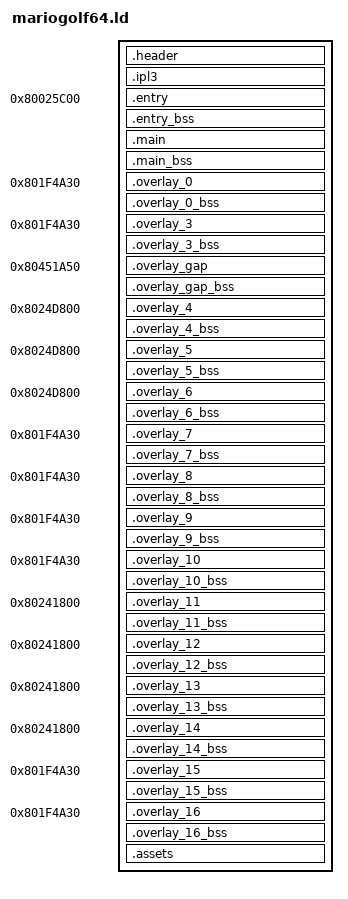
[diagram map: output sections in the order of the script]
SECTIONS
{
    __romPos = 0;
    header_ROM_START = __romPos;
    header_VRAM = ADDR(.header);
    .header : AT(header_ROM_START)
    {
        FILL(0x00000000);
        header_DATA_START = .;
        build/asm/header.o(.data);
        header_DATA_END = .;
        header_DATA_SIZE = ABSOLUTE(header_DATA_END - header_DATA_START);
    }
    __romPos += SIZEOF(.header);
    header_ROM_END = __romPos;
    header_VRAM_END = .;

    ipl3_ROM_START = __romPos;
    ipl3_VRAM = ADDR(.ipl3);
    .ipl3 : AT(ipl3_ROM_START)
    {
        FILL(0x00000000);
        ipl3_DATA_START = .;
        build/assets/ipl3.o(.data);
        ipl3_DATA_END = .;
        ipl3_DATA_SIZE = ABSOLUTE(ipl3_DATA_END - ipl3_DATA_START);
    }
    __romPos += SIZEOF(.ipl3);
    ipl3_ROM_END = __romPos;
    ipl3_VRAM_END = .;

    entry_ROM_START = __romPos;
    entry_VRAM = ADDR(.entry);
    .entry 0x80025C00 : AT(entry_ROM_START)
    {
        FILL(0x00000000);
        entry_TEXT_START = .;
        build/src/entry/entry.o(.text);
        entry_TEXT_END = .;
        entry_TEXT_SIZE = ABSOLUTE(entry_TEXT_END - entry_TEXT_START);
        entry_DATA_START = .;
        build/src/entry/entry.o(.data);
        entry_DATA_END = .;
        entry_DATA_SIZE = ABSOLUTE(entry_DATA_END - entry_DATA_START);
        entry_RODATA_START = .;
        build/src/entry/entry.o(.rodata);
        entry_RODATA_END = .;
        entry_RODATA_SIZE = ABSOLUTE(entry_RODATA_END - entry_RODATA_START);
    }
    entry_bss_VRAM = ADDR(.entry_bss);
    .entry_bss (NOLOAD) :
    {
        FILL(0x00000000);
        entry_BSS_START = .;
        build/src/entry/entry.o(.bss);
        entry_BSS_END = .;
        entry_BSS_SIZE = ABSOLUTE(entry_BSS_END - entry_BSS_START);
    }
    __romPos += SIZEOF(.entry);
    __romPos = ALIGN(__romPos, 16);
    entry_ROM_END = __romPos;
    entry_VRAM_END = .;

    main_ROM_START = __romPos;
    main_VRAM = ADDR(.main);
    .main entry_VRAM_END : AT(main_ROM_START)
    {
        FILL(0x00000000);
        main_TEXT_START = .;
        build/src/libnusys/mainlib/nupireadrom.o(.text);
        build/asm/1130.o(.text);
        build/asm/17B0.o(.text);
        build/src/libnusys/mainlib/nugfxinit.o(.text);
        build/asm/37B0.o(.text);
        build/asm/4650.o(.text);
        build/asm/4840.o(.text);
        build/asm/4CE0.o(.text);
        build/asm/5A40.o(.text);
        build/asm/DCE0.o(.text);
        build/asm/E260.o(.text);
        build/asm/142B0.o(.text);
        build/asm/193D0.o(.text);
        build/asm/1B4A0.o(.text);
        build/asm/1EEF0.o(.text);
        build/asm/207E0.o(.text);
        build/asm/28590.o(.text);
        build/asm/299A0.o(.text);
        build/asm/2B4E0.o(.text);
        build/asm/2B800.o(.text);
        build/asm/2BFF0.o(.text);
        build/asm/2D290.o(.text);
        build/asm/2D5C0.o(.text);
        build/asm/2E3E0.o(.text);
        build/asm/2FD00.o(.text);
        build/asm/34FA0.o(.text);
        build/asm/396C0.o(.text);
        build/asm/40180.o(.text);
        build/asm/414A0.o(.text);
        build/src/mgu/mtxutil.o(.text);
        build/asm/43140.o(.text);
        build/asm/43810.o(.text);
        build/asm/45400.o(.text);
        build/asm/456C0.o(.text);
        build/asm/49E90.o(.text);
        build/asm/4A5A0.o(.text);
        build/asm/4C3D0.o(.text);
        build/asm/4C770.o(.text);
        build/asm/51900.o(.text);
        build/asm/526B0.o(.text);
        build/asm/52FF0.o(.text);
        build/asm/53D10.o(.text);
        build/asm/5B620.o(.text);
        build/asm/68500.o(.text);
        build/asm/70E10.o(.text);
        build/src/main/func_80099490.o(.text);
        build/asm/748B0.o(.text);
        build/asm/78330.o(.text);
        build/asm/78D10.o(.text);
        build/asm/79370.o(.text);
        build/asm/79640.o(.text);
        build/asm/798B0.o(.text);
        build/asm/7A840.o(.text);
        build/asm/7AF60.o(.text);
        build/asm/7B140.o(.text);
        build/asm/7BB30.o(.text);
        build/asm/7BBB0.o(.text);
        build/asm/7BC00.o(.text);
        build/asm/7BDE0.o(.text);
        build/asm/7BE90.o(.text);
        build/asm/7BF20.o(.text);
        build/asm/7BFB0.o(.text);
        build/asm/7C060.o(.text);
        build/asm/7C0F0.o(.text);
        build/asm/7C170.o(.text);
        build/asm/7C6D0.o(.text);
        build/asm/7C720.o(.text);
        build/src/libnusys/mainlib/nuprenmifuncset.o(.text);
        build/asm/7C830.o(.text);
        build/src/libnusys/mainlib/nugfxfuncset.o(.text);
        build/src/libnusys/mainlib/nugfxswapcfbfuncset.o(.text);
        build/src/libnusys/mainlib/nugfxswapcfb.o(.text);
        build/src/libnusys/mainlib/nugfxtaskallendwait.o(.text);
        build/src/libnusys/mainlib/nugfxretracewait.o(.text);
        build/src/libnusys/mainlib/nugfxdisplayoff.o(.text);
        build/src/libnusys/mainlib/nugfxdisplayon.o(.text);
        build/src/libnusys/mainlib/nupiinit.o(.text);
        build/src/libnusys/mainlib/nupiinitsram.o(.text);
        build/src/libnusys/mainlib/nupireadwritesram.o(.text);
        build/src/libnusys/mainlib/nucontinit.o(.text);
        build/src/libnusys/mainlib/nucontdatagetex.o(.text);
        build/asm/7CD60.o(.text);
        build/src/libnusys/mainlib/nucontrmbstart.o(.text);
        build/src/libnusys/mainlib/nucontrmbcheck.o(.text);
        build/asm/7D3B0.o(.text);
        build/asm/7D4A0.o(.text);
        build/src/libnusys/mainlib/nucontgbpakopen.o(.text);
        build/src/libnusys/mainlib/nucontgbpakgetstatus.o(.text);
        build/src/libnusys/mainlib/nucontgbpakpower.o(.text);
        build/src/libnusys/mainlib/nucontgbpakreadid.o(.text);
        build/src/libnusys/mainlib/nucontgbpakreadwrite.o(.text);
        build/src/libnusys/mainlib/nucontgbpakcheck.o(.text);
        build/asm/7D7A0.o(.text);
        build/asm/7D970.o(.text);
        build/asm/7DE70.o(.text);
        build/asm/7DF90.o(.text);
        build/src/libnusys/mainlib/nucontdatalock.o(.text);
        build/src/libnusys/mainlib/nucontqueryread.o(.text);
        build/src/libultra/os/getcurrfaultthread.o(.text);
        build/src/libultra/os/setintmask.o(.text);
        build/src/libultra/io/pimgr.o(.text);
        build/src/libultra/io/epirawdma.o(.text);
        build/src/libultra/io/epidma.o(.text);
        build/src/libultra/io/epilinkhandle.o(.text);
        build/src/libultra/io/cartrominit.o(.text);
        build/src/libultra/io/devmgr.o(.text);
        build/src/libultra/io/piacs.o(.text);
        build/src/libultra/io/aigetlen.o(.text);
        build/src/libultra/io/aigetstat.o(.text);
        build/src/libultra/io/aisetfreq.o(.text);
        build/src/libultra/io/aisetnextbuf.o(.text);
        build/src/libultra/audio/drvrnew.o(.text);
        build/src/libultra/audio/load.o(.text);
        build/src/libultra/audio/auxbus.o(.text);
        build/src/libultra/audio/env.o(.text);
        build/src/libultra/audio/filter.o(.text);
        build/src/libultra/audio/mainbus.o(.text);
        build/src/libultra/audio/resample.o(.text);
        build/src/libultra/audio/reverb.o(.text);
        build/src/libultra/audio/save.o(.text);
        build/src/libultra/audio/sl.o(.text);
        build/src/libultra/audio/heapinit.o(.text);
        build/src/libultra/audio/heapalloc.o(.text);
        build/src/libultra/audio/copy.o(.text);
        build/src/libultra/os/invaldcache.o(.text);
        build/src/libultra/os/invalicache.o(.text);
        build/src/libultra/os/writebackdcache.o(.text);
        build/src/libultra/os/writebackdcacheall.o(.text);
        build/src/libultra/io/contquery.o(.text);
        build/src/libultra/io/contreaddata.o(.text);
        build/src/libultra/io/controller.o(.text);
        build/src/libultra/os/virtualtophysical.o(.text);
        build/src/libultra/gu/align.o(.text);
        build/src/libultra/gu/cosf.o(.text);
        build/src/libultra/gu/lookat.o(.text);
        build/src/libultra/gu/lookathil.o(.text);
        build/src/libultra/gu/lookatref.o(.text);
        build/src/libultra/gu/mtxcatf.o(.text);
        build/src/libultra/gu/mtxcatl.o(.text);
        build/src/libultra/gu/ortho.o(.text);
        build/src/libultra/gu/perspective.o(.text);
        build/src/libultra/gu/position.o(.text);
        build/src/libultra/gu/random.o(.text);
        build/src/libultra/gu/rotate.o(.text);
        build/src/libultra/gu/rotaterpy.o(.text);
        build/src/libultra/gu/scale.o(.text);
        build/src/libultra/gu/sinf.o(.text);
        build/src/libultra/gu/translate.o(.text);
        build/src/libultra/libc/bcopy.o(.text);
        build/src/libultra/libc/bzero.o(.text);
        build/src/libultra/libc/string.o(.text);
        build/src/libultra/libc/sprintf.o(.text);
        build/src/libultra/libc/syncprintf.o(.text);
        build/src/libultra/os/createmesgqueue.o(.text);
        build/src/libultra/os/jammesg.o(.text);
        build/src/libultra/os/recvmesg.o(.text);
        build/src/libultra/os/sendmesg.o(.text);
        build/src/libultra/os/seteventmesg.o(.text);
        build/src/libultra/io/dpsetstat.o(.text);
        build/src/libultra/io/dpctr.o(.text);
        build/src/libultra/os/getcount.o(.text);
        build/src/libultra/io/sptask.o(.text);
        build/src/libultra/io/sptaskyield.o(.text);
        build/src/libultra/io/sptaskyielded.o(.text);
        build/src/libultra/sched/sched.o(.text);
        build/src/libultra/io/sirawdma.o(.text);
        build/src/libultra/io/siacs.o(.text);
        build/src/libultra/os/createthread.o(.text);
        build/src/libultra/os/destroythread.o(.text);
        build/src/libultra/os/getthreadpri.o(.text);
        build/src/libultra/os/setthreadpri.o(.text);
        build/src/libultra/os/startthread.o(.text);
        build/src/libultra/os/stopthread.o(.text);
        build/src/libultra/os/dequeuethread.o(.text);
        build/src/libultra/os/yieldthread.o(.text);
        build/src/libultra/os/gettime.o(.text);
        build/src/libultra/os/settimer.o(.text);
        build/src/libultra/os/timerintr.o(.text);
        build/src/libultra/os/maptlb.o(.text);
        build/src/libultra/os/probetlb.o(.text);
        build/src/libultra/os/unmaptlb.o(.text);
        build/src/libultra/os/unmaptlball.o(.text);
        build/src/libultra/io/vigetcurrframebuf.o(.text);
        build/src/libultra/io/vigetnextframebuf.o(.text);
        build/src/libultra/io/vigetmode.o(.text);
        build/src/libultra/io/vimgr.o(.text);
        build/src/libultra/io/visetevent.o(.text);
        build/src/libultra/io/visetmode.o(.text);
        build/src/libultra/io/visetspecial.o(.text);
        build/src/libultra/io/visetyscale.o(.text);
        build/src/libultra/io/viswapbuf.o(.text);
        build/src/libultra/io/viswapcontext.o(.text);
        build/src/libultra/io/viblack.o(.text);
        build/src/libultra/io/gbpakinit.o(.text);
        build/src/libultra/io/gbpakgetstatus.o(.text);
        build/src/libultra/io/gbpakpower.o(.text);
        build/src/libultra/io/gbpakreadwrite.o(.text);
        build/src/libultra/io/gbpakreadid.o(.text);
        build/src/libultra/io/gbpakcheckconnector.o(.text);
        build/src/libultra/io/motor.o(.text);
        build/src/libultra/io/pfsgetstatus.o(.text);
        build/src/libultra/io/pfsselectbank.o(.text);
        build/src/libultra/io/contpfs.o(.text);
        build/src/libultra/io/contramread.o(.text);
        build/src/libultra/io/contramwrite.o(.text);
        build/src/libultra/os/parameters.o(.text);
        build/src/libultra/os/afterprenmi.o(.text);
        build/src/libultra/os/initialize.o(.text);
        build/src/libultra/os/exceptasm.o(.text);
        build/src/libultra/os/interrupt.o(.text);
        build/src/libultra/os/setglobalintmask.o(.text);
        build/src/libultra/os/resetglobalintmask.o(.text);
        build/src/libultra/io/pirawdma.o(.text);
        build/src/libultra/io/pigetcmdq.o(.text);
        build/src/libultra/io/epirawread.o(.text);
        build/src/libultra/io/epirawwrite.o(.text);
        build/src/libultra/io/ai.o(.text);
        build/src/libultra/gu/sqrtf.o(.text);
        build/src/libultra/libc/bcmp.o(.text);
        build/src/libultra/libc/xprintf.o(.text);
        build/src/libultra/io/dpsetnextbuf.o(.text);
        build/src/libultra/os/getcause.o(.text);
        build/src/libultra/os/getsr.o(.text);
        build/src/libultra/os/setcompare.o(.text);
        build/src/libultra/os/setfpccsr.o(.text);
        build/src/libultra/os/setsr.o(.text);
        build/src/libultra/os/setwatchlo.o(.text);
        build/src/libultra/io/sp.o(.text);
        build/src/libultra/io/spgetstat.o(.text);
        build/src/libultra/io/spsetstat.o(.text);
        build/src/libultra/io/spsetpc.o(.text);
        build/src/libultra/io/sprawdma.o(.text);
        build/src/libultra/io/sirawread.o(.text);
        build/src/libultra/io/sirawwrite.o(.text);
        build/src/libultra/io/crc.o(.text);
        build/src/libultra/os/maptlbrdb.o(.text);
        build/src/libultra/io/viinit.o(.text);
        build/src/libultra/io/vigetcurrcontext.o(.text);
        build/src/libultra/io/gbpaksetbank.o(.text);
        build/src/libultra/io/pfsisplug.o(.text);
        build/src/libultra/libc/xlitob.o(.text);
        build/src/libultra/libc/xldtob.o(.text);
        build/src/libultra/io/dp.o(.text);
        build/src/libultra/io/si.o(.text);
        build/src/libultra/libc/ldiv.o(.text);
        build/src/libkmc/atan.o(.text);
        build/src/libkmc/memset.o(.text);
        build/src/libkmc/rand.o(.text);
        build/asm/8E660.o(.text);
        build/src/libkmc/strcmp.o(.text);
        build/src/libkmc/_matherr.o(.text);
        build/src/libkmc/mmuldi3.o(.text);
        build/src/libkmc/mcvtld.o(.text);
        build/src/libkmc/matherr.o(.text);
        build/asm/8F250.o(.text);
        main_TEXT_END = .;
        main_TEXT_SIZE = ABSOLUTE(main_TEXT_END - main_TEXT_START);
        main_DATA_START = .;
        build/src/libnusys/mainlib/nupireadrom.o(.data);
        build/asm/1130.o(.data);
        build/asm/17B0.o(.data);
        build/src/libnusys/mainlib/nugfxinit.o(.data);
        build/asm/37B0.o(.data);
        build/asm/4650.o(.data);
        build/asm/4840.o(.data);
        build/asm/4CE0.o(.data);
        build/asm/5A40.o(.data);
        build/asm/DCE0.o(.data);
        build/asm/E260.o(.data);
        build/asm/142B0.o(.data);
        build/asm/193D0.o(.data);
        build/asm/1B4A0.o(.data);
        build/asm/1EEF0.o(.data);
        build/asm/207E0.o(.data);
        build/asm/28590.o(.data);
        build/asm/299A0.o(.data);
        build/asm/2B4E0.o(.data);
        build/asm/2B800.o(.data);
        build/asm/2BFF0.o(.data);
        build/asm/2D290.o(.data);
        build/asm/2D5C0.o(.data);
        build/asm/2E3E0.o(.data);
        build/asm/2FD00.o(.data);
        build/asm/34FA0.o(.data);
        build/asm/396C0.o(.data);
        build/asm/40180.o(.data);
        build/asm/414A0.o(.data);
        build/src/mgu/mtxutil.o(.data);
        build/asm/43140.o(.data);
        build/asm/43810.o(.data);
        build/asm/45400.o(.data);
        build/asm/456C0.o(.data);
        build/asm/49E90.o(.data);
        build/asm/4A5A0.o(.data);
        build/asm/4C3D0.o(.data);
        build/asm/4C770.o(.data);
        build/asm/51900.o(.data);
        build/asm/526B0.o(.data);
        build/asm/52FF0.o(.data);
        build/asm/53D10.o(.data);
        build/asm/5B620.o(.data);
        build/asm/68500.o(.data);
        build/asm/70E10.o(.data);
        build/src/main/func_80099490.o(.data);
        build/asm/748B0.o(.data);
        build/asm/78330.o(.data);
        build/asm/78D10.o(.data);
        build/asm/79370.o(.data);
        build/asm/79640.o(.data);
        build/asm/798B0.o(.data);
        build/asm/7A840.o(.data);
        build/asm/7AF60.o(.data);
        build/asm/7B140.o(.data);
        build/asm/7BB30.o(.data);
        build/asm/7BBB0.o(.data);
        build/asm/7BC00.o(.data);
        build/asm/7BDE0.o(.data);
        build/asm/7BE90.o(.data);
        build/asm/7BF20.o(.data);
        build/asm/7BFB0.o(.data);
        build/asm/7C060.o(.data);
        build/asm/7C0F0.o(.data);
        build/asm/7C170.o(.data);
        build/asm/7C6D0.o(.data);
        build/asm/7C720.o(.data);
        build/src/libnusys/mainlib/nuprenmifuncset.o(.data);
        build/asm/7C830.o(.data);
        build/src/libnusys/mainlib/nugfxfuncset.o(.data);
        build/src/libnusys/mainlib/nugfxswapcfbfuncset.o(.data);
        build/src/libnusys/mainlib/nugfxswapcfb.o(.data);
        build/src/libnusys/mainlib/nugfxtaskallendwait.o(.data);
        build/src/libnusys/mainlib/nugfxretracewait.o(.data);
        build/src/libnusys/mainlib/nugfxdisplayoff.o(.data);
        build/src/libnusys/mainlib/nugfxdisplayon.o(.data);
        build/src/libnusys/mainlib/nupiinit.o(.data);
        build/src/libnusys/mainlib/nupiinitsram.o(.data);
        build/src/libnusys/mainlib/nupireadwritesram.o(.data);
        build/src/libnusys/mainlib/nucontinit.o(.data);
        build/src/libnusys/mainlib/nucontdatagetex.o(.data);
        build/asm/7CD60.o(.data);
        build/src/libnusys/mainlib/nucontrmbstart.o(.data);
        build/src/libnusys/mainlib/nucontrmbcheck.o(.data);
        build/asm/7D3B0.o(.data);
        build/asm/7D4A0.o(.data);
        build/src/libnusys/mainlib/nucontgbpakopen.o(.data);
        build/src/libnusys/mainlib/nucontgbpakgetstatus.o(.data);
        build/src/libnusys/mainlib/nucontgbpakpower.o(.data);
        build/src/libnusys/mainlib/nucontgbpakreadid.o(.data);
        build/src/libnusys/mainlib/nucontgbpakreadwrite.o(.data);
        build/src/libnusys/mainlib/nucontgbpakcheck.o(.data);
        build/asm/7D7A0.o(.data);
        build/asm/7D970.o(.data);
        build/asm/7DE70.o(.data);
        build/asm/7DF90.o(.data);
        build/src/libnusys/mainlib/nucontdatalock.o(.data);
        build/src/libnusys/mainlib/nucontqueryread.o(.data);
        build/src/libultra/os/getcurrfaultthread.o(.data);
        build/src/libultra/os/setintmask.o(.data);
        build/src/libultra/io/pimgr.o(.data);
        build/src/libultra/io/epirawdma.o(.data);
        build/src/libultra/io/epidma.o(.data);
        build/src/libultra/io/epilinkhandle.o(.data);
        build/src/libultra/io/cartrominit.o(.data);
        build/src/libultra/io/devmgr.o(.data);
        build/src/libultra/io/piacs.o(.data);
        build/src/libultra/io/aigetlen.o(.data);
        build/src/libultra/io/aigetstat.o(.data);
        build/src/libultra/io/aisetfreq.o(.data);
        build/src/libultra/io/aisetnextbuf.o(.data);
        build/asm/data/main_data.data.o(.data);
        build/src/libultra/audio/drvrnew.o(.data);
        build/src/libultra/audio/load.o(.data);
        build/src/libultra/audio/auxbus.o(.data);
        build/src/libultra/audio/env.o(.data);
        build/src/libultra/audio/filter.o(.data);
        build/src/libultra/audio/mainbus.o(.data);
        build/src/libultra/audio/resample.o(.data);
        build/src/libultra/audio/reverb.o(.data);
        build/src/libultra/audio/save.o(.data);
        build/src/libultra/audio/sl.o(.data);
        build/src/libultra/audio/heapinit.o(.data);
        build/src/libultra/audio/heapalloc.o(.data);
        build/src/libultra/audio/copy.o(.data);
        build/src/libultra/os/invaldcache.o(.data);
        build/src/libultra/os/invalicache.o(.data);
        build/src/libultra/os/writebackdcache.o(.data);
        build/src/libultra/os/writebackdcacheall.o(.data);
        build/src/libultra/io/contquery.o(.data);
        build/src/libultra/io/contreaddata.o(.data);
        build/src/libultra/io/controller.o(.data);
        build/src/libultra/os/virtualtophysical.o(.data);
        build/src/libultra/gu/align.o(.data);
        build/src/libultra/gu/cosf.o(.data);
        build/src/libultra/gu/lookat.o(.data);
        build/src/libultra/gu/lookathil.o(.data);
        build/src/libultra/gu/lookatref.o(.data);
        build/src/libultra/gu/mtxcatf.o(.data);
        build/src/libultra/gu/mtxcatl.o(.data);
        build/src/libultra/gu/ortho.o(.data);
        build/src/libultra/gu/perspective.o(.data);
        build/src/libultra/gu/position.o(.data);
        build/src/libultra/gu/random.o(.data);
        build/src/libultra/gu/rotate.o(.data);
        build/src/libultra/gu/rotaterpy.o(.data);
        build/src/libultra/gu/scale.o(.data);
        build/src/libultra/gu/sinf.o(.data);
        build/src/libultra/gu/translate.o(.data);
        build/src/libultra/libc/bcopy.o(.data);
        build/src/libultra/libc/bzero.o(.data);
        build/src/libultra/libc/string.o(.data);
        build/src/libultra/libc/sprintf.o(.data);
        build/src/libultra/libc/syncprintf.o(.data);
        build/src/libultra/os/createmesgqueue.o(.data);
        build/src/libultra/os/jammesg.o(.data);
        build/src/libultra/os/recvmesg.o(.data);
        build/src/libultra/os/sendmesg.o(.data);
        build/src/libultra/os/seteventmesg.o(.data);
        build/src/libultra/io/dpsetstat.o(.data);
        build/src/libultra/io/dpctr.o(.data);
        build/src/libultra/os/getcount.o(.data);
        build/src/libultra/io/sptask.o(.data);
        build/src/libultra/io/sptaskyield.o(.data);
        build/src/libultra/io/sptaskyielded.o(.data);
        build/src/libultra/sched/sched.o(.data);
        build/src/libultra/io/sirawdma.o(.data);
        build/src/libultra/io/siacs.o(.data);
        build/src/libultra/os/createthread.o(.data);
        build/src/libultra/os/destroythread.o(.data);
        build/src/libultra/os/getthreadpri.o(.data);
        build/src/libultra/os/setthreadpri.o(.data);
        build/src/libultra/os/startthread.o(.data);
        build/src/libultra/os/stopthread.o(.data);
        build/src/libultra/os/dequeuethread.o(.data);
        build/src/libultra/os/yieldthread.o(.data);
        build/src/libultra/os/gettime.o(.data);
        build/src/libultra/os/settimer.o(.data);
        build/src/libultra/os/thread.o(.data);
        build/src/libultra/os/timerintr.o(.data);
        build/src/libultra/os/maptlb.o(.data);
        build/src/libultra/os/probetlb.o(.data);
        build/src/libultra/os/unmaptlb.o(.data);
        build/src/libultra/os/unmaptlball.o(.data);
        build/src/libultra/io/vigetcurrframebuf.o(.data);
        build/src/libultra/io/vigetnextframebuf.o(.data);
        build/src/libultra/io/vigetmode.o(.data);
        build/src/libultra/io/vimgr.o(.data);
        build/src/libultra/io/visetevent.o(.data);
        build/src/libultra/io/visetmode.o(.data);
        build/src/libultra/io/visetspecial.o(.data);
        build/src/libultra/io/visetyscale.o(.data);
        build/src/libultra/io/viswapbuf.o(.data);
        build/src/libultra/io/viswapcontext.o(.data);
        build/src/libultra/io/viblack.o(.data);
        build/src/libultra/io/gbpakinit.o(.data);
        build/src/libultra/io/gbpakgetstatus.o(.data);
        build/src/libultra/io/gbpakpower.o(.data);
        build/src/libultra/io/gbpakreadwrite.o(.data);
        build/src/libultra/io/vitbl.o(.data);
        build/src/libultra/io/gbpakreadid.o(.data);
        build/src/libultra/io/gbpakcheckconnector.o(.data);
        build/src/libultra/io/motor.o(.data);
        build/src/libultra/io/pfsgetstatus.o(.data);
        build/src/libultra/io/pfsselectbank.o(.data);
        build/src/libultra/io/contpfs.o(.data);
        build/src/libultra/io/contramread.o(.data);
        build/src/libultra/io/contramwrite.o(.data);
        build/src/libultra/os/parameters.o(.data);
        build/src/libultra/os/afterprenmi.o(.data);
        build/src/libultra/os/initialize.o(.data);
        build/src/libultra/os/exceptasm.o(.data);
        build/src/libultra/os/interrupt.o(.data);
        build/src/libultra/os/setglobalintmask.o(.data);
        build/src/libultra/os/resetglobalintmask.o(.data);
        build/src/libultra/io/pirawdma.o(.data);
        build/src/libultra/io/pigetcmdq.o(.data);
        build/src/libultra/io/epirawread.o(.data);
        build/src/libultra/io/epirawwrite.o(.data);
        build/src/libultra/io/ai.o(.data);
        build/src/libultra/gu/sqrtf.o(.data);
        build/src/libultra/libc/bcmp.o(.data);
        build/src/libultra/libc/xprintf.o(.data);
        build/src/libultra/io/dpsetnextbuf.o(.data);
        build/src/libultra/os/getcause.o(.data);
        build/src/libultra/os/getsr.o(.data);
        build/src/libultra/os/setcompare.o(.data);
        build/src/libultra/os/setfpccsr.o(.data);
        build/src/libultra/os/setsr.o(.data);
        build/src/libultra/os/setwatchlo.o(.data);
        build/src/libultra/io/sp.o(.data);
        build/src/libultra/io/spgetstat.o(.data);
        build/src/libultra/io/spsetstat.o(.data);
        build/src/libultra/io/spsetpc.o(.data);
        build/src/libultra/io/sprawdma.o(.data);
        build/src/libultra/io/sirawread.o(.data);
        build/src/libultra/io/sirawwrite.o(.data);
        build/src/libultra/io/crc.o(.data);
        build/src/libultra/os/maptlbrdb.o(.data);
        build/src/libultra/io/viinit.o(.data);
        build/src/libultra/io/vigetcurrcontext.o(.data);
        build/src/libultra/io/gbpaksetbank.o(.data);
        build/src/libultra/io/pfsisplug.o(.data);
        build/src/libultra/io/vi.o(.data);
        build/src/libultra/vimodes/vimodentsclan1.o(.data);
        build/src/libultra/vimodes/vimodepallan1.o(.data);
        build/src/libultra/vimodes/vimodempallan1.o(.data);
        build/src/libultra/libc/xlitob.o(.data);
        build/src/libultra/libc/xldtob.o(.data);
        build/src/libultra/io/dp.o(.data);
        build/src/libultra/io/si.o(.data);
        build/src/libultra/libc/ldiv.o(.data);
        build/src/libkmc/atan.o(.data);
        build/src/libkmc/memset.o(.data);
        build/src/libkmc/rand.o(.data);
        build/asm/8E660.o(.data);
        build/src/libkmc/strcmp.o(.data);
        build/src/libkmc/_matherr.o(.data);
        build/src/libkmc/mmuldi3.o(.data);
        build/src/libkmc/mcvtld.o(.data);
        build/src/libkmc/matherr.o(.data);
        build/asm/8F250.o(.data);
        build/asm/data/A4A90.data.o(.data);
        main_DATA_END = .;
        main_DATA_SIZE = ABSOLUTE(main_DATA_END - main_DATA_START);
        main_RODATA_START = .;
        build/src/libnusys/mainlib/nupireadrom.o(.rodata);
        build/asm/1130.o(.rodata);
        build/asm/17B0.o(.rodata);
        build/src/libnusys/mainlib/nugfxinit.o(.rodata);
        build/asm/37B0.o(.rodata);
        build/asm/4650.o(.rodata);
        build/asm/4840.o(.rodata);
        build/asm/4CE0.o(.rodata);
        build/asm/5A40.o(.rodata);
        build/asm/DCE0.o(.rodata);
        build/asm/E260.o(.rodata);
        build/asm/142B0.o(.rodata);
        build/asm/193D0.o(.rodata);
        build/asm/1B4A0.o(.rodata);
        build/asm/1EEF0.o(.rodata);
        build/asm/207E0.o(.rodata);
        build/asm/28590.o(.rodata);
        build/asm/299A0.o(.rodata);
        build/asm/2B4E0.o(.rodata);
        build/asm/2B800.o(.rodata);
        build/asm/2BFF0.o(.rodata);
        build/asm/2D290.o(.rodata);
        build/asm/2D5C0.o(.rodata);
        build/asm/2E3E0.o(.rodata);
        build/asm/2FD00.o(.rodata);
        build/asm/34FA0.o(.rodata);
        build/asm/396C0.o(.rodata);
        build/asm/40180.o(.rodata);
        build/asm/414A0.o(.rodata);
        build/src/mgu/mtxutil.o(.rodata);
        build/asm/43140.o(.rodata);
        build/asm/43810.o(.rodata);
        build/asm/45400.o(.rodata);
        build/asm/456C0.o(.rodata);
        build/asm/49E90.o(.rodata);
        build/asm/4A5A0.o(.rodata);
        build/asm/4C3D0.o(.rodata);
        build/asm/4C770.o(.rodata);
        build/asm/51900.o(.rodata);
        build/asm/526B0.o(.rodata);
        build/asm/52FF0.o(.rodata);
        build/asm/53D10.o(.rodata);
        build/asm/5B620.o(.rodata);
        build/asm/68500.o(.rodata);
        build/asm/70E10.o(.rodata);
        build/src/main/func_80099490.o(.rodata);
        build/asm/748B0.o(.rodata);
        build/asm/78330.o(.rodata);
        build/asm/78D10.o(.rodata);
        build/asm/79370.o(.rodata);
        build/asm/79640.o(.rodata);
        build/asm/798B0.o(.rodata);
        build/asm/7A840.o(.rodata);
        build/asm/7AF60.o(.rodata);
        build/asm/7B140.o(.rodata);
        build/asm/7BB30.o(.rodata);
        build/asm/7BBB0.o(.rodata);
        build/asm/7BC00.o(.rodata);
        build/asm/7BDE0.o(.rodata);
        build/asm/7BE90.o(.rodata);
        build/asm/7BF20.o(.rodata);
        build/asm/7BFB0.o(.rodata);
        build/asm/7C060.o(.rodata);
        build/asm/7C0F0.o(.rodata);
        build/asm/7C170.o(.rodata);
        build/asm/7C6D0.o(.rodata);
        build/asm/7C720.o(.rodata);
        build/src/libnusys/mainlib/nuprenmifuncset.o(.rodata);
        build/asm/7C830.o(.rodata);
        build/src/libnusys/mainlib/nugfxfuncset.o(.rodata);
        build/src/libnusys/mainlib/nugfxswapcfbfuncset.o(.rodata);
        build/src/libnusys/mainlib/nugfxswapcfb.o(.rodata);
        build/src/libnusys/mainlib/nugfxtaskallendwait.o(.rodata);
        build/src/libnusys/mainlib/nugfxretracewait.o(.rodata);
        build/src/libnusys/mainlib/nugfxdisplayoff.o(.rodata);
        build/src/libnusys/mainlib/nugfxdisplayon.o(.rodata);
        build/src/libnusys/mainlib/nupiinit.o(.rodata);
        build/src/libnusys/mainlib/nupiinitsram.o(.rodata);
        build/src/libnusys/mainlib/nupireadwritesram.o(.rodata);
        build/src/libnusys/mainlib/nucontinit.o(.rodata);
        build/src/libnusys/mainlib/nucontdatagetex.o(.rodata);
        build/asm/7CD60.o(.rodata);
        build/src/libnusys/mainlib/nucontrmbstart.o(.rodata);
        build/src/libnusys/mainlib/nucontrmbcheck.o(.rodata);
        build/asm/7D3B0.o(.rodata);
        build/asm/7D4A0.o(.rodata);
        build/src/libnusys/mainlib/nucontgbpakopen.o(.rodata);
        build/src/libnusys/mainlib/nucontgbpakgetstatus.o(.rodata);
        build/src/libnusys/mainlib/nucontgbpakpower.o(.rodata);
        build/src/libnusys/mainlib/nucontgbpakreadid.o(.rodata);
        build/src/libnusys/mainlib/nucontgbpakreadwrite.o(.rodata);
        build/src/libnusys/mainlib/nucontgbpakcheck.o(.rodata);
        build/asm/7D7A0.o(.rodata);
        build/asm/7D970.o(.rodata);
        build/asm/7DE70.o(.rodata);
        build/asm/7DF90.o(.rodata);
        build/src/libnusys/mainlib/nucontdatalock.o(.rodata);
        build/src/libnusys/mainlib/nucontqueryread.o(.rodata);
        build/src/libultra/os/getcurrfaultthread.o(.rodata);
        build/src/libultra/os/setintmask.o(.rodata);
        build/src/libultra/io/pimgr.o(.rodata);
        build/src/libultra/io/epirawdma.o(.rodata);
        build/src/libultra/io/epidma.o(.rodata);
        build/src/libultra/io/epilinkhandle.o(.rodata);
        build/src/libultra/io/cartrominit.o(.rodata);
        build/asm/data/main_rodata.rodata.o(.rodata);
        build/asm/data/A5CE0.rodata.o(.rodata);
        build/asm/data/A5D30.rodata.o(.rodata);
        build/asm/data/A5FD0.rodata.o(.rodata);
        build/asm/data/AC760.rodata.o(.rodata);
        build/asm/data/AC770.rodata.o(.rodata);
        build/asm/data/ACAD0.rodata.o(.rodata);
        build/asm/data/ACD00.rodata.o(.rodata);
        build/asm/data/AD490.rodata.o(.rodata);
        build/asm/data/AD520.rodata.o(.rodata);
        build/asm/data/AD590.rodata.o(.rodata);
        build/asm/data/AD5A0.rodata.o(.rodata);
        build/asm/data/AD5E0.rodata.o(.rodata);
        build/src/libultra/io/devmgr.o(.rodata);
        build/src/libultra/io/piacs.o(.rodata);
        build/src/libultra/io/aigetlen.o(.rodata);
        build/src/libultra/io/aigetstat.o(.rodata);
        build/src/libultra/io/aisetfreq.o(.rodata);
        build/src/libultra/io/aisetnextbuf.o(.rodata);
        build/src/libultra/audio/drvrnew.o(.rodata);
        build/src/libultra/audio/load.o(.rodata);
        build/src/libultra/audio/auxbus.o(.rodata);
        build/src/libultra/audio/env.o(.rodata);
        build/src/libultra/audio/filter.o(.rodata);
        build/src/libultra/audio/mainbus.o(.rodata);
        build/src/libultra/audio/resample.o(.rodata);
        build/src/libultra/audio/reverb.o(.rodata);
        build/src/libultra/audio/save.o(.rodata);
        build/src/libultra/audio/sl.o(.rodata);
        build/src/libultra/audio/heapinit.o(.rodata);
        build/src/libultra/audio/heapalloc.o(.rodata);
        build/src/libultra/audio/copy.o(.rodata);
        build/src/libultra/os/invaldcache.o(.rodata);
        build/src/libultra/os/invalicache.o(.rodata);
        build/src/libultra/os/writebackdcache.o(.rodata);
        build/src/libultra/os/writebackdcacheall.o(.rodata);
        build/src/libultra/io/contquery.o(.rodata);
        build/src/libultra/io/contreaddata.o(.rodata);
        build/src/libultra/io/controller.o(.rodata);
        build/src/libultra/os/virtualtophysical.o(.rodata);
        build/src/libultra/gu/align.o(.rodata);
        build/src/libultra/gu/cosf.o(.rodata);
        build/src/libultra/gu/lookat.o(.rodata);
        build/src/libultra/gu/lookathil.o(.rodata);
        build/src/libultra/gu/lookatref.o(.rodata);
        build/src/libultra/gu/mtxcatf.o(.rodata);
        build/src/libultra/gu/mtxcatl.o(.rodata);
        build/src/libultra/gu/ortho.o(.rodata);
        build/src/libultra/gu/perspective.o(.rodata);
        build/src/libultra/gu/position.o(.rodata);
        build/src/libultra/gu/random.o(.rodata);
        build/src/libultra/gu/rotate.o(.rodata);
        build/src/libultra/gu/rotaterpy.o(.rodata);
        build/src/libultra/gu/scale.o(.rodata);
        build/src/libultra/gu/sinf.o(.rodata);
        build/src/libultra/gu/translate.o(.rodata);
        build/src/libultra/libc/bcopy.o(.rodata);
        build/src/libultra/libc/bzero.o(.rodata);
        build/src/libultra/libc/string.o(.rodata);
        build/src/libultra/libc/sprintf.o(.rodata);
        build/src/libultra/libc/syncprintf.o(.rodata);
        build/src/libultra/os/createmesgqueue.o(.rodata);
        build/src/libultra/os/jammesg.o(.rodata);
        build/src/libultra/os/recvmesg.o(.rodata);
        build/src/libultra/os/sendmesg.o(.rodata);
        build/src/libultra/os/seteventmesg.o(.rodata);
        build/src/libultra/io/dpsetstat.o(.rodata);
        build/src/libultra/io/dpctr.o(.rodata);
        build/src/libultra/os/getcount.o(.rodata);
        build/src/libultra/io/sptask.o(.rodata);
        build/src/libultra/io/sptaskyield.o(.rodata);
        build/src/libultra/io/sptaskyielded.o(.rodata);
        build/src/libultra/sched/sched.o(.rodata);
        build/src/libultra/io/sirawdma.o(.rodata);
        build/src/libultra/io/siacs.o(.rodata);
        build/src/libultra/os/createthread.o(.rodata);
        build/src/libultra/os/destroythread.o(.rodata);
        build/src/libultra/os/getthreadpri.o(.rodata);
        build/src/libultra/os/setthreadpri.o(.rodata);
        build/src/libultra/os/startthread.o(.rodata);
        build/src/libultra/os/stopthread.o(.rodata);
        build/src/libultra/os/dequeuethread.o(.rodata);
        build/src/libultra/os/yieldthread.o(.rodata);
        build/src/libultra/os/gettime.o(.rodata);
        build/src/libultra/os/settimer.o(.rodata);
        build/src/libultra/os/timerintr.o(.rodata);
        build/src/libultra/os/maptlb.o(.rodata);
        build/src/libultra/os/probetlb.o(.rodata);
        build/src/libultra/os/unmaptlb.o(.rodata);
        build/src/libultra/os/unmaptlball.o(.rodata);
        build/src/libultra/io/vigetcurrframebuf.o(.rodata);
        build/src/libultra/io/vigetnextframebuf.o(.rodata);
        build/src/libultra/io/vigetmode.o(.rodata);
        build/src/libultra/io/vimgr.o(.rodata);
        build/src/libultra/io/visetevent.o(.rodata);
        build/src/libultra/io/visetmode.o(.rodata);
        build/src/libultra/io/visetspecial.o(.rodata);
        build/src/libultra/io/visetyscale.o(.rodata);
        build/src/libultra/io/viswapbuf.o(.rodata);
        build/src/libultra/io/viswapcontext.o(.rodata);
        build/src/libultra/io/viblack.o(.rodata);
        build/src/libultra/io/gbpakinit.o(.rodata);
        build/src/libultra/io/gbpakgetstatus.o(.rodata);
        build/src/libultra/io/gbpakpower.o(.rodata);
        build/src/libultra/io/gbpakreadwrite.o(.rodata);
        build/src/libultra/io/gbpakreadid.o(.rodata);
        build/src/libultra/io/gbpakcheckconnector.o(.rodata);
        build/src/libultra/io/motor.o(.rodata);
        build/src/libultra/io/pfsgetstatus.o(.rodata);
        build/src/libultra/io/pfsselectbank.o(.rodata);
        build/src/libultra/io/contpfs.o(.rodata);
        build/src/libultra/io/contramread.o(.rodata);
        build/src/libultra/io/contramwrite.o(.rodata);
        build/src/libultra/os/parameters.o(.rodata);
        build/src/libultra/os/afterprenmi.o(.rodata);
        build/src/libultra/os/initialize.o(.rodata);
        build/src/libultra/os/exceptasm.o(.rodata);
        build/src/libultra/os/interrupt.o(.rodata);
        build/src/libultra/os/setglobalintmask.o(.rodata);
        build/src/libultra/os/resetglobalintmask.o(.rodata);
        build/src/libultra/io/pirawdma.o(.rodata);
        build/src/libultra/io/pigetcmdq.o(.rodata);
        build/src/libultra/io/epirawread.o(.rodata);
        build/src/libultra/io/epirawwrite.o(.rodata);
        build/src/libultra/io/ai.o(.rodata);
        build/src/libultra/gu/sqrtf.o(.rodata);
        build/src/libultra/libc/bcmp.o(.rodata);
        build/src/libultra/gu/libm_vals.o(.rodata);
        build/src/libultra/libc/xprintf.o(.rodata);
        build/src/libultra/io/dpsetnextbuf.o(.rodata);
        build/src/libultra/os/getcause.o(.rodata);
        build/src/libultra/os/getsr.o(.rodata);
        build/src/libultra/os/setcompare.o(.rodata);
        build/src/libultra/os/setfpccsr.o(.rodata);
        build/src/libultra/os/setsr.o(.rodata);
        build/src/libultra/os/setwatchlo.o(.rodata);
        build/src/libultra/io/sp.o(.rodata);
        build/src/libultra/io/spgetstat.o(.rodata);
        build/src/libultra/io/spsetstat.o(.rodata);
        build/src/libultra/io/spsetpc.o(.rodata);
        build/src/libultra/io/sprawdma.o(.rodata);
        build/src/libultra/io/sirawread.o(.rodata);
        build/src/libultra/io/sirawwrite.o(.rodata);
        build/src/libultra/io/crc.o(.rodata);
        build/src/libultra/os/maptlbrdb.o(.rodata);
        build/src/libultra/io/viinit.o(.rodata);
        build/src/libultra/io/vigetcurrcontext.o(.rodata);
        build/src/libultra/io/gbpaksetbank.o(.rodata);
        build/src/libultra/io/pfsisplug.o(.rodata);
        build/src/libultra/libc/xlitob.o(.rodata);
        build/src/libultra/libc/xldtob.o(.rodata);
        build/src/libultra/io/dp.o(.rodata);
        build/src/libultra/io/si.o(.rodata);
        build/src/libultra/libc/ldiv.o(.rodata);
        build/src/libkmc/atan.o(.rodata);
        build/src/libkmc/memset.o(.rodata);
        build/src/libkmc/rand.o(.rodata);
        build/asm/8E660.o(.rodata);
        build/src/libkmc/strcmp.o(.rodata);
        build/src/libkmc/_matherr.o(.rodata);
        build/src/libkmc/mmuldi3.o(.rodata);
        build/src/libkmc/mcvtld.o(.rodata);
        build/src/libkmc/matherr.o(.rodata);
        build/asm/8F250.o(.rodata);
        build/asm/data/ADCA0.rodata.o(.rodata);
        main_RODATA_END = .;
        main_RODATA_SIZE = ABSOLUTE(main_RODATA_END - main_RODATA_START);
    }
    main_bss_VRAM = ADDR(.main_bss);
    .main_bss (NOLOAD) :
    {
        FILL(0x00000000);
        main_BSS_START = .;
        build/src/libnusys/mainlib/nupireadrom.o(.bss);
        build/asm/1130.o(.bss);
        build/asm/17B0.o(.bss);
        build/src/libnusys/mainlib/nugfxinit.o(.bss);
        build/asm/37B0.o(.bss);
        build/asm/4650.o(.bss);
        build/asm/4840.o(.bss);
        build/asm/4CE0.o(.bss);
        build/asm/5A40.o(.bss);
        build/asm/DCE0.o(.bss);
        build/asm/E260.o(.bss);
        build/asm/142B0.o(.bss);
        build/asm/193D0.o(.bss);
        build/asm/1B4A0.o(.bss);
        build/asm/1EEF0.o(.bss);
        build/asm/207E0.o(.bss);
        build/asm/28590.o(.bss);
        build/asm/299A0.o(.bss);
        build/asm/2B4E0.o(.bss);
        build/asm/2B800.o(.bss);
        build/asm/2BFF0.o(.bss);
        build/asm/2D290.o(.bss);
        build/asm/2D5C0.o(.bss);
        build/asm/2E3E0.o(.bss);
        build/asm/2FD00.o(.bss);
        build/asm/34FA0.o(.bss);
        build/asm/396C0.o(.bss);
        build/asm/40180.o(.bss);
        build/asm/414A0.o(.bss);
        build/src/mgu/mtxutil.o(.bss);
        build/asm/43140.o(.bss);
        build/asm/43810.o(.bss);
        build/asm/45400.o(.bss);
        build/asm/456C0.o(.bss);
        build/asm/49E90.o(.bss);
        build/asm/4A5A0.o(.bss);
        build/asm/4C3D0.o(.bss);
        build/asm/4C770.o(.bss);
        build/asm/51900.o(.bss);
        build/asm/526B0.o(.bss);
        build/asm/52FF0.o(.bss);
        build/asm/53D10.o(.bss);
        build/asm/5B620.o(.bss);
        build/asm/68500.o(.bss);
        build/asm/70E10.o(.bss);
        build/src/main/func_80099490.o(.bss);
        build/asm/748B0.o(.bss);
        build/asm/78330.o(.bss);
        build/asm/78D10.o(.bss);
        build/asm/79370.o(.bss);
        build/asm/79640.o(.bss);
        build/asm/798B0.o(.bss);
        build/asm/7A840.o(.bss);
        build/asm/7AF60.o(.bss);
        build/asm/7B140.o(.bss);
        build/asm/7BB30.o(.bss);
        build/asm/7BBB0.o(.bss);
        build/asm/7BC00.o(.bss);
        build/asm/7BDE0.o(.bss);
        build/asm/7BE90.o(.bss);
        build/asm/7BF20.o(.bss);
        build/asm/7BFB0.o(.bss);
        build/asm/7C060.o(.bss);
        build/asm/7C0F0.o(.bss);
        build/asm/7C170.o(.bss);
        build/asm/7C6D0.o(.bss);
        build/asm/7C720.o(.bss);
        build/src/libnusys/mainlib/nuprenmifuncset.o(.bss);
        build/asm/7C830.o(.bss);
        build/src/libnusys/mainlib/nugfxfuncset.o(.bss);
        build/src/libnusys/mainlib/nugfxswapcfbfuncset.o(.bss);
        build/src/libnusys/mainlib/nugfxswapcfb.o(.bss);
        build/src/libnusys/mainlib/nugfxtaskallendwait.o(.bss);
        build/src/libnusys/mainlib/nugfxretracewait.o(.bss);
        build/src/libnusys/mainlib/nugfxdisplayoff.o(.bss);
        build/src/libnusys/mainlib/nugfxdisplayon.o(.bss);
        build/src/libnusys/mainlib/nupiinit.o(.bss);
        build/src/libnusys/mainlib/nupiinitsram.o(.bss);
        build/src/libnusys/mainlib/nupireadwritesram.o(.bss);
        build/src/libnusys/mainlib/nucontinit.o(.bss);
        build/src/libnusys/mainlib/nucontdatagetex.o(.bss);
        build/asm/7CD60.o(.bss);
        build/src/libnusys/mainlib/nucontrmbstart.o(.bss);
        build/src/libnusys/mainlib/nucontrmbcheck.o(.bss);
        build/asm/7D3B0.o(.bss);
        build/asm/7D4A0.o(.bss);
        build/src/libnusys/mainlib/nucontgbpakopen.o(.bss);
        build/src/libnusys/mainlib/nucontgbpakgetstatus.o(.bss);
        build/src/libnusys/mainlib/nucontgbpakpower.o(.bss);
        build/src/libnusys/mainlib/nucontgbpakreadid.o(.bss);
        build/src/libnusys/mainlib/nucontgbpakreadwrite.o(.bss);
        build/src/libnusys/mainlib/nucontgbpakcheck.o(.bss);
        build/asm/7D7A0.o(.bss);
        build/asm/7D970.o(.bss);
        build/asm/7DE70.o(.bss);
        build/asm/7DF90.o(.bss);
        build/src/libnusys/mainlib/nucontdatalock.o(.bss);
        build/src/libnusys/mainlib/nucontqueryread.o(.bss);
        build/src/libultra/os/getcurrfaultthread.o(.bss);
        build/src/libultra/os/setintmask.o(.bss);
        build/src/libultra/io/pimgr.o(.bss);
        build/src/libultra/io/epirawdma.o(.bss);
        build/src/libultra/io/epidma.o(.bss);
        build/src/libultra/io/epilinkhandle.o(.bss);
        build/src/libultra/io/cartrominit.o(.bss);
        build/src/libultra/io/devmgr.o(.bss);
        build/src/libultra/io/piacs.o(.bss);
        build/src/libultra/io/aigetlen.o(.bss);
        build/src/libultra/io/aigetstat.o(.bss);
        build/src/libultra/io/aisetfreq.o(.bss);
        build/src/libultra/io/aisetnextbuf.o(.bss);
        build/src/libultra/audio/drvrnew.o(.bss);
        build/src/libultra/audio/load.o(.bss);
        build/src/libultra/audio/auxbus.o(.bss);
        build/src/libultra/audio/env.o(.bss);
        build/src/libultra/audio/filter.o(.bss);
        build/src/libultra/audio/mainbus.o(.bss);
        build/src/libultra/audio/resample.o(.bss);
        build/src/libultra/audio/reverb.o(.bss);
        build/src/libultra/audio/save.o(.bss);
        build/src/libultra/audio/sl.o(.bss);
        build/src/libultra/audio/heapinit.o(.bss);
        build/src/libultra/audio/heapalloc.o(.bss);
        build/src/libultra/audio/copy.o(.bss);
        build/src/libultra/os/invaldcache.o(.bss);
        build/src/libultra/os/invalicache.o(.bss);
        build/src/libultra/os/writebackdcache.o(.bss);
        build/src/libultra/os/writebackdcacheall.o(.bss);
        build/src/libultra/io/contquery.o(.bss);
        build/src/libultra/io/contreaddata.o(.bss);
        build/src/libultra/io/controller.o(.bss);
        build/src/libultra/os/virtualtophysical.o(.bss);
        build/src/libultra/gu/align.o(.bss);
        build/src/libultra/gu/cosf.o(.bss);
        build/src/libultra/gu/lookat.o(.bss);
        build/src/libultra/gu/lookathil.o(.bss);
        build/src/libultra/gu/lookatref.o(.bss);
        build/src/libultra/gu/mtxcatf.o(.bss);
        build/src/libultra/gu/mtxcatl.o(.bss);
        build/src/libultra/gu/ortho.o(.bss);
        build/src/libultra/gu/perspective.o(.bss);
        build/src/libultra/gu/position.o(.bss);
        build/src/libultra/gu/random.o(.bss);
        build/src/libultra/gu/rotate.o(.bss);
        build/src/libultra/gu/rotaterpy.o(.bss);
        build/src/libultra/gu/scale.o(.bss);
        build/src/libultra/gu/sinf.o(.bss);
        build/src/libultra/gu/translate.o(.bss);
        build/src/libultra/libc/bcopy.o(.bss);
        build/src/libultra/libc/bzero.o(.bss);
        build/src/libultra/libc/string.o(.bss);
        build/src/libultra/libc/sprintf.o(.bss);
        build/src/libultra/libc/syncprintf.o(.bss);
        build/src/libultra/os/createmesgqueue.o(.bss);
        build/src/libultra/os/jammesg.o(.bss);
        build/src/libultra/os/recvmesg.o(.bss);
        build/src/libultra/os/sendmesg.o(.bss);
        build/src/libultra/os/seteventmesg.o(.bss);
        build/src/libultra/io/dpsetstat.o(.bss);
        build/src/libultra/io/dpctr.o(.bss);
        build/src/libultra/os/getcount.o(.bss);
        build/src/libultra/io/sptask.o(.bss);
        build/src/libultra/io/sptaskyield.o(.bss);
        build/src/libultra/io/sptaskyielded.o(.bss);
        build/src/libultra/sched/sched.o(.bss);
        build/src/libultra/io/sirawdma.o(.bss);
        build/src/libultra/io/siacs.o(.bss);
        build/src/libultra/os/createthread.o(.bss);
        build/src/libultra/os/destroythread.o(.bss);
        build/src/libultra/os/getthreadpri.o(.bss);
        build/src/libultra/os/setthreadpri.o(.bss);
        build/src/libultra/os/startthread.o(.bss);
        build/src/libultra/os/stopthread.o(.bss);
        build/src/libultra/os/dequeuethread.o(.bss);
        build/src/libultra/os/yieldthread.o(.bss);
        build/src/libultra/os/gettime.o(.bss);
        build/src/libultra/os/settimer.o(.bss);
        build/src/libultra/os/timerintr.o(.bss);
        build/src/libultra/os/maptlb.o(.bss);
        build/src/libultra/os/probetlb.o(.bss);
        build/src/libultra/os/unmaptlb.o(.bss);
        build/src/libultra/os/unmaptlball.o(.bss);
        build/src/libultra/io/vigetcurrframebuf.o(.bss);
        build/src/libultra/io/vigetnextframebuf.o(.bss);
        build/src/libultra/io/vigetmode.o(.bss);
        build/src/libultra/io/vimgr.o(.bss);
        build/src/libultra/io/visetevent.o(.bss);
        build/src/libultra/io/visetmode.o(.bss);
        build/src/libultra/io/visetspecial.o(.bss);
        build/src/libultra/io/visetyscale.o(.bss);
        build/src/libultra/io/viswapbuf.o(.bss);
        build/src/libultra/io/viswapcontext.o(.bss);
        build/src/libultra/io/viblack.o(.bss);
        build/src/libultra/io/gbpakinit.o(.bss);
        build/src/libultra/io/gbpakgetstatus.o(.bss);
        build/src/libultra/io/gbpakpower.o(.bss);
        build/src/libultra/io/gbpakreadwrite.o(.bss);
        build/src/libultra/io/gbpakreadid.o(.bss);
        build/src/libultra/io/gbpakcheckconnector.o(.bss);
        build/src/libultra/io/motor.o(.bss);
        build/src/libultra/io/pfsgetstatus.o(.bss);
        build/src/libultra/io/pfsselectbank.o(.bss);
        build/src/libultra/io/contpfs.o(.bss);
        build/src/libultra/io/contramread.o(.bss);
        build/src/libultra/io/contramwrite.o(.bss);
        build/src/libultra/os/parameters.o(.bss);
        build/src/libultra/os/afterprenmi.o(.bss);
        build/src/libultra/os/initialize.o(.bss);
        build/src/libultra/os/exceptasm.o(.bss);
        build/src/libultra/os/interrupt.o(.bss);
        build/src/libultra/os/setglobalintmask.o(.bss);
        build/src/libultra/os/resetglobalintmask.o(.bss);
        build/src/libultra/io/pirawdma.o(.bss);
        build/src/libultra/io/pigetcmdq.o(.bss);
        build/src/libultra/io/epirawread.o(.bss);
        build/src/libultra/io/epirawwrite.o(.bss);
        build/src/libultra/io/ai.o(.bss);
        build/src/libultra/gu/sqrtf.o(.bss);
        build/src/libultra/libc/bcmp.o(.bss);
        build/src/libultra/libc/xprintf.o(.bss);
        build/src/libultra/io/dpsetnextbuf.o(.bss);
        build/src/libultra/os/getcause.o(.bss);
        build/src/libultra/os/getsr.o(.bss);
        build/src/libultra/os/setcompare.o(.bss);
        build/src/libultra/os/setfpccsr.o(.bss);
        build/src/libultra/os/setsr.o(.bss);
        build/src/libultra/os/setwatchlo.o(.bss);
        build/src/libultra/io/sp.o(.bss);
        build/src/libultra/io/spgetstat.o(.bss);
        build/src/libultra/io/spsetstat.o(.bss);
        build/src/libultra/io/spsetpc.o(.bss);
        build/src/libultra/io/sprawdma.o(.bss);
        build/src/libultra/io/sirawread.o(.bss);
        build/src/libultra/io/sirawwrite.o(.bss);
        build/src/libultra/io/crc.o(.bss);
        build/src/libultra/os/maptlbrdb.o(.bss);
        build/src/libultra/io/viinit.o(.bss);
        build/src/libultra/io/vigetcurrcontext.o(.bss);
        build/src/libultra/io/gbpaksetbank.o(.bss);
        build/src/libultra/io/pfsisplug.o(.bss);
        build/src/libultra/libc/xlitob.o(.bss);
        build/src/libultra/libc/xldtob.o(.bss);
        build/src/libultra/io/dp.o(.bss);
        build/src/libultra/io/si.o(.bss);
        build/src/libultra/libc/ldiv.o(.bss);
        build/src/libkmc/atan.o(.bss);
        build/src/libkmc/memset.o(.bss);
        build/src/libkmc/rand.o(.bss);
        build/asm/8E660.o(.bss);
        build/src/libkmc/strcmp.o(.bss);
        build/src/libkmc/_matherr.o(.bss);
        build/src/libkmc/mmuldi3.o(.bss);
        build/src/libkmc/mcvtld.o(.bss);
        build/src/libkmc/matherr.o(.bss);
        build/asm/8F250.o(.bss);
        build/asm/data/ADD30.bss.o(.bss);
        main_BSS_END = .;
        main_BSS_SIZE = ABSOLUTE(main_BSS_END - main_BSS_START);
    }
    __romPos += SIZEOF(.main);
    __romPos = ALIGN(__romPos, 16);
    main_ROM_END = __romPos;
    main_VRAM_END = .;

    overlay_0_ROM_START = __romPos;
    overlay_0_VRAM = ADDR(.overlay_0);
    .overlay_0 0x801F4A30 : AT(overlay_0_ROM_START)
    {
        FILL(0x00000000);
        overlay_0_TEXT_START = .;
        build/asm/ADD30.o(.text);
        build/asm/ADD40.o(.text);
        build/asm/B68F0.o(.text);
        build/asm/BBD00.o(.text);
        build/asm/C7A40.o(.text);
        build/asm/CFE10.o(.text);
        build/asm/D1FC0.o(.text);
        build/asm/D4330.o(.text);
        build/asm/D71D0.o(.text);
        build/asm/D7850.o(.text);
        overlay_0_TEXT_END = .;
        overlay_0_TEXT_SIZE = ABSOLUTE(overlay_0_TEXT_END - overlay_0_TEXT_START);
        overlay_0_DATA_START = .;
        build/asm/ADD30.o(.data);
        build/asm/ADD40.o(.data);
        build/asm/B68F0.o(.data);
        build/asm/BBD00.o(.data);
        build/asm/C7A40.o(.data);
        build/asm/CFE10.o(.data);
        build/asm/D1FC0.o(.data);
        build/asm/D4330.o(.data);
        build/asm/D71D0.o(.data);
        build/asm/D7850.o(.data);
        build/asm/data/D8F70.data.o(.data);
        overlay_0_DATA_END = .;
        overlay_0_DATA_SIZE = ABSOLUTE(overlay_0_DATA_END - overlay_0_DATA_START);
        overlay_0_RODATA_START = .;
        build/asm/ADD30.o(.rodata);
        build/asm/ADD40.o(.rodata);
        build/asm/B68F0.o(.rodata);
        build/asm/BBD00.o(.rodata);
        build/asm/C7A40.o(.rodata);
        build/asm/CFE10.o(.rodata);
        build/asm/D1FC0.o(.rodata);
        build/asm/D4330.o(.rodata);
        build/asm/D71D0.o(.rodata);
        build/asm/D7850.o(.rodata);
        overlay_0_RODATA_END = .;
        overlay_0_RODATA_SIZE = ABSOLUTE(overlay_0_RODATA_END - overlay_0_RODATA_START);
    }
    overlay_0_bss_VRAM = ADDR(.overlay_0_bss);
    .overlay_0_bss (NOLOAD) :
    {
        FILL(0x00000000);
        overlay_0_BSS_START = .;
        build/asm/ADD30.o(.bss);
        build/asm/ADD40.o(.bss);
        build/asm/B68F0.o(.bss);
        build/asm/BBD00.o(.bss);
        build/asm/C7A40.o(.bss);
        build/asm/CFE10.o(.bss);
        build/asm/D1FC0.o(.bss);
        build/asm/D4330.o(.bss);
        build/asm/D71D0.o(.bss);
        build/asm/D7850.o(.bss);
        build/asm/data/DE9B0.bss.o(.bss);
        overlay_0_BSS_END = .;
        overlay_0_BSS_SIZE = ABSOLUTE(overlay_0_BSS_END - overlay_0_BSS_START);
    }
    __romPos += SIZEOF(.overlay_0);
    __romPos = ALIGN(__romPos, 16);
    overlay_0_ROM_END = __romPos;
    overlay_0_VRAM_END = .;

    overlay_3_ROM_START = __romPos;
    overlay_3_VRAM = ADDR(.overlay_3);
    .overlay_3 0x801F4A30 : AT(overlay_3_ROM_START)
    {
        FILL(0x00000000);
        overlay_3_TEXT_START = .;
        build/asm/DE9B0.o(.text);
        build/asm/DE9C0.o(.text);
        build/asm/F3480.o(.text);
        build/asm/F7F90.o(.text);
        build/asm/FD310.o(.text);
        build/asm/FF940.o(.text);
        build/asm/101830.o(.text);
        build/asm/109570.o(.text);
        build/asm/110670.o(.text);
        overlay_3_TEXT_END = .;
        overlay_3_TEXT_SIZE = ABSOLUTE(overlay_3_TEXT_END - overlay_3_TEXT_START);
        overlay_3_DATA_START = .;
        build/asm/DE9B0.o(.data);
        build/asm/DE9C0.o(.data);
        build/asm/F3480.o(.data);
        build/asm/F7F90.o(.data);
        build/asm/FD310.o(.data);
        build/asm/FF940.o(.data);
        build/asm/101830.o(.data);
        build/asm/109570.o(.data);
        build/asm/110670.o(.data);
        build/asm/data/115D80.data.o(.data);
        overlay_3_DATA_END = .;
        overlay_3_DATA_SIZE = ABSOLUTE(overlay_3_DATA_END - overlay_3_DATA_START);
        overlay_3_RODATA_START = .;
        build/asm/DE9B0.o(.rodata);
        build/asm/DE9C0.o(.rodata);
        build/asm/F3480.o(.rodata);
        build/asm/F7F90.o(.rodata);
        build/asm/FD310.o(.rodata);
        build/asm/FF940.o(.rodata);
        build/asm/101830.o(.rodata);
        build/asm/109570.o(.rodata);
        build/asm/110670.o(.rodata);
        overlay_3_RODATA_END = .;
        overlay_3_RODATA_SIZE = ABSOLUTE(overlay_3_RODATA_END - overlay_3_RODATA_START);
    }
    overlay_3_bss_VRAM = ADDR(.overlay_3_bss);
    .overlay_3_bss (NOLOAD) :
    {
        FILL(0x00000000);
        overlay_3_BSS_START = .;
        build/asm/DE9B0.o(.bss);
        build/asm/DE9C0.o(.bss);
        build/asm/F3480.o(.bss);
        build/asm/F7F90.o(.bss);
        build/asm/FD310.o(.bss);
        build/asm/FF940.o(.bss);
        build/asm/101830.o(.bss);
        build/asm/109570.o(.bss);
        build/asm/110670.o(.bss);
        build/asm/data/11BA50.bss.o(.bss);
        overlay_3_BSS_END = .;
        overlay_3_BSS_SIZE = ABSOLUTE(overlay_3_BSS_END - overlay_3_BSS_START);
    }
    __romPos += SIZEOF(.overlay_3);
    __romPos = ALIGN(__romPos, 16);
    overlay_3_ROM_END = __romPos;
    overlay_3_VRAM_END = .;

    overlay_gap_ROM_START = __romPos;
    overlay_gap_VRAM = ADDR(.overlay_gap);
    .overlay_gap 0x80451A50 : AT(overlay_gap_ROM_START)
    {
        FILL(0x00000000);
        overlay_gap_TEXT_START = .;
        build/asm/11BA50.o(.text);
        overlay_gap_TEXT_END = .;
        overlay_gap_TEXT_SIZE = ABSOLUTE(overlay_gap_TEXT_END - overlay_gap_TEXT_START);
        overlay_gap_DATA_START = .;
        build/asm/11BA50.o(.data);
        overlay_gap_DATA_END = .;
        overlay_gap_DATA_SIZE = ABSOLUTE(overlay_gap_DATA_END - overlay_gap_DATA_START);
        overlay_gap_RODATA_START = .;
        build/asm/11BA50.o(.rodata);
        overlay_gap_RODATA_END = .;
        overlay_gap_RODATA_SIZE = ABSOLUTE(overlay_gap_RODATA_END - overlay_gap_RODATA_START);
    }
    overlay_gap_bss_VRAM = ADDR(.overlay_gap_bss);
    .overlay_gap_bss (NOLOAD) :
    {
        FILL(0x00000000);
        overlay_gap_BSS_START = .;
        build/asm/11BA50.o(.bss);
        overlay_gap_BSS_END = .;
        overlay_gap_BSS_SIZE = ABSOLUTE(overlay_gap_BSS_END - overlay_gap_BSS_START);
    }
    __romPos += SIZEOF(.overlay_gap);
    __romPos = ALIGN(__romPos, 16);
    overlay_gap_ROM_END = __romPos;
    overlay_gap_VRAM_END = .;

    overlay_4_ROM_START = __romPos;
    overlay_4_VRAM = ADDR(.overlay_4);
    .overlay_4 0x8024D800 : AT(overlay_4_ROM_START)
    {
        FILL(0x00000000);
        overlay_4_TEXT_START = .;
        build/asm/128580.o(.text);
        overlay_4_TEXT_END = .;
        overlay_4_TEXT_SIZE = ABSOLUTE(overlay_4_TEXT_END - overlay_4_TEXT_START);
        overlay_4_DATA_START = .;
        build/asm/128580.o(.data);
        build/asm/data/12F020.data.o(.data);
        overlay_4_DATA_END = .;
        overlay_4_DATA_SIZE = ABSOLUTE(overlay_4_DATA_END - overlay_4_DATA_START);
        overlay_4_RODATA_START = .;
        build/asm/128580.o(.rodata);
        overlay_4_RODATA_END = .;
        overlay_4_RODATA_SIZE = ABSOLUTE(overlay_4_RODATA_END - overlay_4_RODATA_START);
    }
    overlay_4_bss_VRAM = ADDR(.overlay_4_bss);
    .overlay_4_bss (NOLOAD) :
    {
        FILL(0x00000000);
        overlay_4_BSS_START = .;
        build/asm/128580.o(.bss);
        build/asm/data/1300A0.bss.o(.bss);
        overlay_4_BSS_END = .;
        overlay_4_BSS_SIZE = ABSOLUTE(overlay_4_BSS_END - overlay_4_BSS_START);
    }
    __romPos += SIZEOF(.overlay_4);
    __romPos = ALIGN(__romPos, 16);
    overlay_4_ROM_END = __romPos;
    overlay_4_VRAM_END = .;

    overlay_5_ROM_START = __romPos;
    overlay_5_VRAM = ADDR(.overlay_5);
    .overlay_5 0x8024D800 : AT(overlay_5_ROM_START)
    {
        FILL(0x00000000);
        overlay_5_TEXT_START = .;
        build/asm/1300A0.o(.text);
        overlay_5_TEXT_END = .;
        overlay_5_TEXT_SIZE = ABSOLUTE(overlay_5_TEXT_END - overlay_5_TEXT_START);
        overlay_5_DATA_START = .;
        build/asm/1300A0.o(.data);
        build/asm/data/1363F0.data.o(.data);
        overlay_5_DATA_END = .;
        overlay_5_DATA_SIZE = ABSOLUTE(overlay_5_DATA_END - overlay_5_DATA_START);
        overlay_5_RODATA_START = .;
        build/asm/1300A0.o(.rodata);
        overlay_5_RODATA_END = .;
        overlay_5_RODATA_SIZE = ABSOLUTE(overlay_5_RODATA_END - overlay_5_RODATA_START);
    }
    overlay_5_bss_VRAM = ADDR(.overlay_5_bss);
    .overlay_5_bss (NOLOAD) :
    {
        FILL(0x00000000);
        overlay_5_BSS_START = .;
        build/asm/1300A0.o(.bss);
        build/asm/data/136BA0.bss.o(.bss);
        overlay_5_BSS_END = .;
        overlay_5_BSS_SIZE = ABSOLUTE(overlay_5_BSS_END - overlay_5_BSS_START);
    }
    __romPos += SIZEOF(.overlay_5);
    __romPos = ALIGN(__romPos, 16);
    overlay_5_ROM_END = __romPos;
    overlay_5_VRAM_END = .;

    overlay_6_ROM_START = __romPos;
    overlay_6_VRAM = ADDR(.overlay_6);
    .overlay_6 0x8024D800 : AT(overlay_6_ROM_START)
    {
        FILL(0x00000000);
        overlay_6_TEXT_START = .;
        build/asm/136BA0.o(.text);
        overlay_6_TEXT_END = .;
        overlay_6_TEXT_SIZE = ABSOLUTE(overlay_6_TEXT_END - overlay_6_TEXT_START);
        overlay_6_DATA_START = .;
        build/asm/136BA0.o(.data);
        build/asm/data/137090.data.o(.data);
        overlay_6_DATA_END = .;
        overlay_6_DATA_SIZE = ABSOLUTE(overlay_6_DATA_END - overlay_6_DATA_START);
        overlay_6_RODATA_START = .;
        build/asm/136BA0.o(.rodata);
        overlay_6_RODATA_END = .;
        overlay_6_RODATA_SIZE = ABSOLUTE(overlay_6_RODATA_END - overlay_6_RODATA_START);
    }
    overlay_6_bss_VRAM = ADDR(.overlay_6_bss);
    .overlay_6_bss (NOLOAD) :
    {
        FILL(0x00000000);
        overlay_6_BSS_START = .;
        build/asm/136BA0.o(.bss);
        build/asm/data/1370B0.bss.o(.bss);
        overlay_6_BSS_END = .;
        overlay_6_BSS_SIZE = ABSOLUTE(overlay_6_BSS_END - overlay_6_BSS_START);
    }
    __romPos += SIZEOF(.overlay_6);
    __romPos = ALIGN(__romPos, 16);
    overlay_6_ROM_END = __romPos;
    overlay_6_VRAM_END = .;

    overlay_7_ROM_START = __romPos;
    overlay_7_VRAM = ADDR(.overlay_7);
    .overlay_7 0x801F4A30 : AT(overlay_7_ROM_START)
    {
        FILL(0x00000000);
        overlay_7_TEXT_START = .;
        build/asm/1370B0.o(.text);
        build/asm/1370C0.o(.text);
        build/asm/145A30.o(.text);
        build/asm/148D00.o(.text);
        overlay_7_TEXT_END = .;
        overlay_7_TEXT_SIZE = ABSOLUTE(overlay_7_TEXT_END - overlay_7_TEXT_START);
        overlay_7_DATA_START = .;
        build/asm/1370B0.o(.data);
        build/asm/1370C0.o(.data);
        build/asm/145A30.o(.data);
        build/asm/148D00.o(.data);
        build/asm/data/14D2C0.data.o(.data);
        overlay_7_DATA_END = .;
        overlay_7_DATA_SIZE = ABSOLUTE(overlay_7_DATA_END - overlay_7_DATA_START);
        overlay_7_RODATA_START = .;
        build/asm/1370B0.o(.rodata);
        build/asm/1370C0.o(.rodata);
        build/asm/145A30.o(.rodata);
        build/asm/148D00.o(.rodata);
        overlay_7_RODATA_END = .;
        overlay_7_RODATA_SIZE = ABSOLUTE(overlay_7_RODATA_END - overlay_7_RODATA_START);
    }
    overlay_7_bss_VRAM = ADDR(.overlay_7_bss);
    .overlay_7_bss (NOLOAD) :
    {
        FILL(0x00000000);
        overlay_7_BSS_START = .;
        build/asm/1370B0.o(.bss);
        build/asm/1370C0.o(.bss);
        build/asm/145A30.o(.bss);
        build/asm/148D00.o(.bss);
        build/asm/data/14EA70.bss.o(.bss);
        overlay_7_BSS_END = .;
        overlay_7_BSS_SIZE = ABSOLUTE(overlay_7_BSS_END - overlay_7_BSS_START);
    }
    __romPos += SIZEOF(.overlay_7);
    __romPos = ALIGN(__romPos, 16);
    overlay_7_ROM_END = __romPos;
    overlay_7_VRAM_END = .;

    overlay_8_ROM_START = __romPos;
    overlay_8_VRAM = ADDR(.overlay_8);
    .overlay_8 0x801F4A30 : AT(overlay_8_ROM_START)
    {
        FILL(0x00000000);
        overlay_8_TEXT_START = .;
        build/asm/14EA70.o(.text);
        build/asm/14EA80.o(.text);
        build/asm/14F5E0.o(.text);
        overlay_8_TEXT_END = .;
        overlay_8_TEXT_SIZE = ABSOLUTE(overlay_8_TEXT_END - overlay_8_TEXT_START);
        overlay_8_DATA_START = .;
        build/asm/14EA70.o(.data);
        build/asm/14EA80.o(.data);
        build/asm/14F5E0.o(.data);
        build/asm/data/14F960.data.o(.data);
        overlay_8_DATA_END = .;
        overlay_8_DATA_SIZE = ABSOLUTE(overlay_8_DATA_END - overlay_8_DATA_START);
        overlay_8_RODATA_START = .;
        build/asm/14EA70.o(.rodata);
        build/asm/14EA80.o(.rodata);
        build/asm/14F5E0.o(.rodata);
        overlay_8_RODATA_END = .;
        overlay_8_RODATA_SIZE = ABSOLUTE(overlay_8_RODATA_END - overlay_8_RODATA_START);
    }
    overlay_8_bss_VRAM = ADDR(.overlay_8_bss);
    .overlay_8_bss (NOLOAD) :
    {
        FILL(0x00000000);
        overlay_8_BSS_START = .;
        build/asm/14EA70.o(.bss);
        build/asm/14EA80.o(.bss);
        build/asm/14F5E0.o(.bss);
        build/asm/data/14FB50.bss.o(.bss);
        overlay_8_BSS_END = .;
        overlay_8_BSS_SIZE = ABSOLUTE(overlay_8_BSS_END - overlay_8_BSS_START);
    }
    __romPos += SIZEOF(.overlay_8);
    __romPos = ALIGN(__romPos, 16);
    overlay_8_ROM_END = __romPos;
    overlay_8_VRAM_END = .;

    overlay_9_ROM_START = __romPos;
    overlay_9_VRAM = ADDR(.overlay_9);
    .overlay_9 0x801F4A30 : AT(overlay_9_ROM_START)
    {
        FILL(0x00000000);
        overlay_9_TEXT_START = .;
        build/asm/14FB50.o(.text);
        build/asm/14FB60.o(.text);
        overlay_9_TEXT_END = .;
        overlay_9_TEXT_SIZE = ABSOLUTE(overlay_9_TEXT_END - overlay_9_TEXT_START);
        overlay_9_DATA_START = .;
        build/asm/14FB50.o(.data);
        build/asm/14FB60.o(.data);
        build/asm/data/150890.data.o(.data);
        overlay_9_DATA_END = .;
        overlay_9_DATA_SIZE = ABSOLUTE(overlay_9_DATA_END - overlay_9_DATA_START);
        overlay_9_RODATA_START = .;
        build/asm/14FB50.o(.rodata);
        build/asm/14FB60.o(.rodata);
        overlay_9_RODATA_END = .;
        overlay_9_RODATA_SIZE = ABSOLUTE(overlay_9_RODATA_END - overlay_9_RODATA_START);
    }
    overlay_9_bss_VRAM = ADDR(.overlay_9_bss);
    .overlay_9_bss (NOLOAD) :
    {
        FILL(0x00000000);
        overlay_9_BSS_START = .;
        build/asm/14FB50.o(.bss);
        build/asm/14FB60.o(.bss);
        build/asm/data/1508D0.bss.o(.bss);
        overlay_9_BSS_END = .;
        overlay_9_BSS_SIZE = ABSOLUTE(overlay_9_BSS_END - overlay_9_BSS_START);
    }
    __romPos += SIZEOF(.overlay_9);
    __romPos = ALIGN(__romPos, 16);
    overlay_9_ROM_END = __romPos;
    overlay_9_VRAM_END = .;

    overlay_10_ROM_START = __romPos;
    overlay_10_VRAM = ADDR(.overlay_10);
    .overlay_10 0x801F4A30 : AT(overlay_10_ROM_START)
    {
        FILL(0x00000000);
        overlay_10_TEXT_START = .;
        build/asm/1508D0.o(.text);
        build/asm/1508E0.o(.text);
        overlay_10_TEXT_END = .;
        overlay_10_TEXT_SIZE = ABSOLUTE(overlay_10_TEXT_END - overlay_10_TEXT_START);
        overlay_10_DATA_START = .;
        build/asm/1508D0.o(.data);
        build/asm/1508E0.o(.data);
        overlay_10_DATA_END = .;
        overlay_10_DATA_SIZE = ABSOLUTE(overlay_10_DATA_END - overlay_10_DATA_START);
        overlay_10_RODATA_START = .;
        build/asm/1508D0.o(.rodata);
        build/asm/1508E0.o(.rodata);
        overlay_10_RODATA_END = .;
        overlay_10_RODATA_SIZE = ABSOLUTE(overlay_10_RODATA_END - overlay_10_RODATA_START);
    }
    overlay_10_bss_VRAM = ADDR(.overlay_10_bss);
    .overlay_10_bss (NOLOAD) :
    {
        FILL(0x00000000);
        overlay_10_BSS_START = .;
        build/asm/1508D0.o(.bss);
        build/asm/1508E0.o(.bss);
        build/asm/data/150990.bss.o(.bss);
        overlay_10_BSS_END = .;
        overlay_10_BSS_SIZE = ABSOLUTE(overlay_10_BSS_END - overlay_10_BSS_START);
    }
    __romPos += SIZEOF(.overlay_10);
    __romPos = ALIGN(__romPos, 16);
    overlay_10_ROM_END = __romPos;
    overlay_10_VRAM_END = .;

    overlay_11_ROM_START = __romPos;
    overlay_11_VRAM = ADDR(.overlay_11);
    .overlay_11 0x80241800 : AT(overlay_11_ROM_START)
    {
        FILL(0x00000000);
        overlay_11_TEXT_START = .;
        build/asm/150990.o(.text);
        build/asm/153560.o(.text);
        overlay_11_TEXT_END = .;
        overlay_11_TEXT_SIZE = ABSOLUTE(overlay_11_TEXT_END - overlay_11_TEXT_START);
        overlay_11_DATA_START = .;
        build/asm/150990.o(.data);
        build/asm/153560.o(.data);
        build/asm/data/15B5E0.data.o(.data);
        overlay_11_DATA_END = .;
        overlay_11_DATA_SIZE = ABSOLUTE(overlay_11_DATA_END - overlay_11_DATA_START);
        overlay_11_RODATA_START = .;
        build/asm/150990.o(.rodata);
        build/asm/153560.o(.rodata);
        overlay_11_RODATA_END = .;
        overlay_11_RODATA_SIZE = ABSOLUTE(overlay_11_RODATA_END - overlay_11_RODATA_START);
    }
    overlay_11_bss_VRAM = ADDR(.overlay_11_bss);
    .overlay_11_bss (NOLOAD) :
    {
        FILL(0x00000000);
        overlay_11_BSS_START = .;
        build/asm/150990.o(.bss);
        build/asm/153560.o(.bss);
        build/asm/data/15BB50.bss.o(.bss);
        overlay_11_BSS_END = .;
        overlay_11_BSS_SIZE = ABSOLUTE(overlay_11_BSS_END - overlay_11_BSS_START);
    }
    __romPos += SIZEOF(.overlay_11);
    __romPos = ALIGN(__romPos, 16);
    overlay_11_ROM_END = __romPos;
    overlay_11_VRAM_END = .;

    overlay_12_ROM_START = __romPos;
    overlay_12_VRAM = ADDR(.overlay_12);
    .overlay_12 0x80241800 : AT(overlay_12_ROM_START)
    {
        FILL(0x00000000);
        overlay_12_TEXT_START = .;
        build/asm/15BB50.o(.text);
        overlay_12_TEXT_END = .;
        overlay_12_TEXT_SIZE = ABSOLUTE(overlay_12_TEXT_END - overlay_12_TEXT_START);
        overlay_12_DATA_START = .;
        build/asm/15BB50.o(.data);
        build/asm/data/15F160.data.o(.data);
        overlay_12_DATA_END = .;
        overlay_12_DATA_SIZE = ABSOLUTE(overlay_12_DATA_END - overlay_12_DATA_START);
        overlay_12_RODATA_START = .;
        build/asm/15BB50.o(.rodata);
        overlay_12_RODATA_END = .;
        overlay_12_RODATA_SIZE = ABSOLUTE(overlay_12_RODATA_END - overlay_12_RODATA_START);
    }
    overlay_12_bss_VRAM = ADDR(.overlay_12_bss);
    .overlay_12_bss (NOLOAD) :
    {
        FILL(0x00000000);
        overlay_12_BSS_START = .;
        build/asm/15BB50.o(.bss);
        build/asm/data/15F250.bss.o(.bss);
        overlay_12_BSS_END = .;
        overlay_12_BSS_SIZE = ABSOLUTE(overlay_12_BSS_END - overlay_12_BSS_START);
    }
    __romPos += SIZEOF(.overlay_12);
    __romPos = ALIGN(__romPos, 16);
    overlay_12_ROM_END = __romPos;
    overlay_12_VRAM_END = .;

    overlay_13_ROM_START = __romPos;
    overlay_13_VRAM = ADDR(.overlay_13);
    .overlay_13 0x80241800 : AT(overlay_13_ROM_START)
    {
        FILL(0x00000000);
        overlay_13_TEXT_START = .;
        build/asm/15F250.o(.text);
        overlay_13_TEXT_END = .;
        overlay_13_TEXT_SIZE = ABSOLUTE(overlay_13_TEXT_END - overlay_13_TEXT_START);
        overlay_13_DATA_START = .;
        build/asm/15F250.o(.data);
        build/asm/data/161870.data.o(.data);
        overlay_13_DATA_END = .;
        overlay_13_DATA_SIZE = ABSOLUTE(overlay_13_DATA_END - overlay_13_DATA_START);
        overlay_13_RODATA_START = .;
        build/asm/15F250.o(.rodata);
        overlay_13_RODATA_END = .;
        overlay_13_RODATA_SIZE = ABSOLUTE(overlay_13_RODATA_END - overlay_13_RODATA_START);
    }
    overlay_13_bss_VRAM = ADDR(.overlay_13_bss);
    .overlay_13_bss (NOLOAD) :
    {
        FILL(0x00000000);
        overlay_13_BSS_START = .;
        build/asm/15F250.o(.bss);
        build/asm/data/1619A0.bss.o(.bss);
        overlay_13_BSS_END = .;
        overlay_13_BSS_SIZE = ABSOLUTE(overlay_13_BSS_END - overlay_13_BSS_START);
    }
    __romPos += SIZEOF(.overlay_13);
    __romPos = ALIGN(__romPos, 16);
    overlay_13_ROM_END = __romPos;
    overlay_13_VRAM_END = .;

    overlay_14_ROM_START = __romPos;
    overlay_14_VRAM = ADDR(.overlay_14);
    .overlay_14 0x80241800 : AT(overlay_14_ROM_START)
    {
        FILL(0x00000000);
        overlay_14_TEXT_START = .;
        build/asm/1619A0.o(.text);
        overlay_14_TEXT_END = .;
        overlay_14_TEXT_SIZE = ABSOLUTE(overlay_14_TEXT_END - overlay_14_TEXT_START);
        overlay_14_DATA_START = .;
        build/asm/1619A0.o(.data);
        build/asm/data/165970.data.o(.data);
        overlay_14_DATA_END = .;
        overlay_14_DATA_SIZE = ABSOLUTE(overlay_14_DATA_END - overlay_14_DATA_START);
        overlay_14_RODATA_START = .;
        build/asm/1619A0.o(.rodata);
        overlay_14_RODATA_END = .;
        overlay_14_RODATA_SIZE = ABSOLUTE(overlay_14_RODATA_END - overlay_14_RODATA_START);
    }
    overlay_14_bss_VRAM = ADDR(.overlay_14_bss);
    .overlay_14_bss (NOLOAD) :
    {
        FILL(0x00000000);
        overlay_14_BSS_START = .;
        build/asm/1619A0.o(.bss);
        build/asm/data/165BC0.bss.o(.bss);
        overlay_14_BSS_END = .;
        overlay_14_BSS_SIZE = ABSOLUTE(overlay_14_BSS_END - overlay_14_BSS_START);
    }
    __romPos += SIZEOF(.overlay_14);
    __romPos = ALIGN(__romPos, 16);
    overlay_14_ROM_END = __romPos;
    overlay_14_VRAM_END = .;

    overlay_15_ROM_START = __romPos;
    overlay_15_VRAM = ADDR(.overlay_15);
    .overlay_15 0x801F4A30 : AT(overlay_15_ROM_START)
    {
        FILL(0x00000000);
        overlay_15_TEXT_START = .;
        build/asm/165BC0.o(.text);
        build/asm/165BD0.o(.text);
        build/asm/16C590.o(.text);
        overlay_15_TEXT_END = .;
        overlay_15_TEXT_SIZE = ABSOLUTE(overlay_15_TEXT_END - overlay_15_TEXT_START);
        overlay_15_DATA_START = .;
        build/asm/165BC0.o(.data);
        build/asm/165BD0.o(.data);
        build/asm/16C590.o(.data);
        build/asm/data/16CCB0.data.o(.data);
        overlay_15_DATA_END = .;
        overlay_15_DATA_SIZE = ABSOLUTE(overlay_15_DATA_END - overlay_15_DATA_START);
        overlay_15_RODATA_START = .;
        build/asm/165BC0.o(.rodata);
        build/asm/165BD0.o(.rodata);
        build/asm/16C590.o(.rodata);
        overlay_15_RODATA_END = .;
        overlay_15_RODATA_SIZE = ABSOLUTE(overlay_15_RODATA_END - overlay_15_RODATA_START);
    }
    overlay_15_bss_VRAM = ADDR(.overlay_15_bss);
    .overlay_15_bss (NOLOAD) :
    {
        FILL(0x00000000);
        overlay_15_BSS_START = .;
        build/asm/165BC0.o(.bss);
        build/asm/165BD0.o(.bss);
        build/asm/16C590.o(.bss);
        build/asm/data/16D650.bss.o(.bss);
        overlay_15_BSS_END = .;
        overlay_15_BSS_SIZE = ABSOLUTE(overlay_15_BSS_END - overlay_15_BSS_START);
    }
    __romPos += SIZEOF(.overlay_15);
    __romPos = ALIGN(__romPos, 16);
    overlay_15_ROM_END = __romPos;
    overlay_15_VRAM_END = .;

    overlay_16_ROM_START = __romPos;
    overlay_16_VRAM = ADDR(.overlay_16);
    .overlay_16 0x801F4A30 : AT(overlay_16_ROM_START)
    {
        FILL(0x00000000);
        overlay_16_TEXT_START = .;
        build/asm/16D650.o(.text);
        build/asm/16D660.o(.text);
        overlay_16_TEXT_END = .;
        overlay_16_TEXT_SIZE = ABSOLUTE(overlay_16_TEXT_END - overlay_16_TEXT_START);
        overlay_16_DATA_START = .;
        build/asm/16D650.o(.data);
        build/asm/16D660.o(.data);
        build/asm/data/1715C0.data.o(.data);
        overlay_16_DATA_END = .;
        overlay_16_DATA_SIZE = ABSOLUTE(overlay_16_DATA_END - overlay_16_DATA_START);
        overlay_16_RODATA_START = .;
        build/asm/16D650.o(.rodata);
        build/asm/16D660.o(.rodata);
        overlay_16_RODATA_END = .;
        overlay_16_RODATA_SIZE = ABSOLUTE(overlay_16_RODATA_END - overlay_16_RODATA_START);
    }
    overlay_16_bss_VRAM = ADDR(.overlay_16_bss);
    .overlay_16_bss (NOLOAD) :
    {
        FILL(0x00000000);
        overlay_16_BSS_START = .;
        build/asm/16D650.o(.bss);
        build/asm/16D660.o(.bss);
        build/asm/data/171770.bss.o(.bss);
        overlay_16_BSS_END = .;
        overlay_16_BSS_SIZE = ABSOLUTE(overlay_16_BSS_END - overlay_16_BSS_START);
    }
    __romPos += SIZEOF(.overlay_16);
    __romPos = ALIGN(__romPos, 16);
    overlay_16_ROM_END = __romPos;
    overlay_16_VRAM_END = .;

    assets_ROM_START = __romPos;
    assets_VRAM = ADDR(.assets);
    .assets : AT(assets_ROM_START)
    {
        FILL(0x00000000);
        assets_DATA_START = .;
        build/assets/assets.o(.data);
        assets_DATA_END = .;
        assets_DATA_SIZE = ABSOLUTE(assets_DATA_END - assets_DATA_START);
    }
    __romPos += SIZEOF(.assets);
    assets_ROM_END = __romPos;
    assets_VRAM_END = .;

    /DISCARD/ :
    {
        *(*);
    }
}
